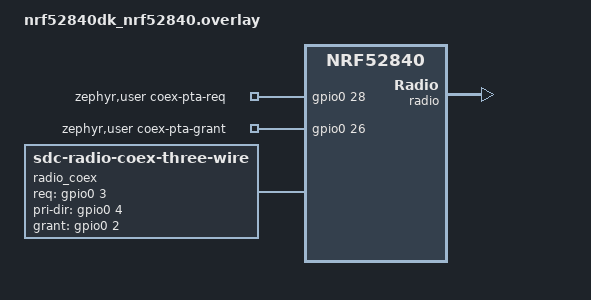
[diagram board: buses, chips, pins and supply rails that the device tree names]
/* Copyright (c) 2021 Nordic Semiconductor ASA
 *
 * SPDX-License-Identifier: LicenseRef-Nordic-5-Clause
 */

/ {
  zephyr,user {
    coex-pta-req-gpios =   <&gpio0 28 GPIO_ACTIVE_HIGH>;
    coex-pta-grant-gpios = <&gpio0 26 GPIO_ACTIVE_HIGH>;
  };

  radio_coex: radio_coex_three_wire {
    status = "okay";
    compatible = "sdc-radio-coex-three-wire";
    req-gpios =     <&gpio0 3 GPIO_ACTIVE_HIGH>;
    pri-dir-gpios = <&gpio0 4 GPIO_ACTIVE_HIGH>;
    grant-gpios =   <&gpio0 2 GPIO_ACTIVE_HIGH>;
    type-delay-us = <8>;
    radio-delay-us = <5>;
    /delete-property/ is-rx-active-level;
  };
};

&radio {
  coex = <&radio_coex>;
};
